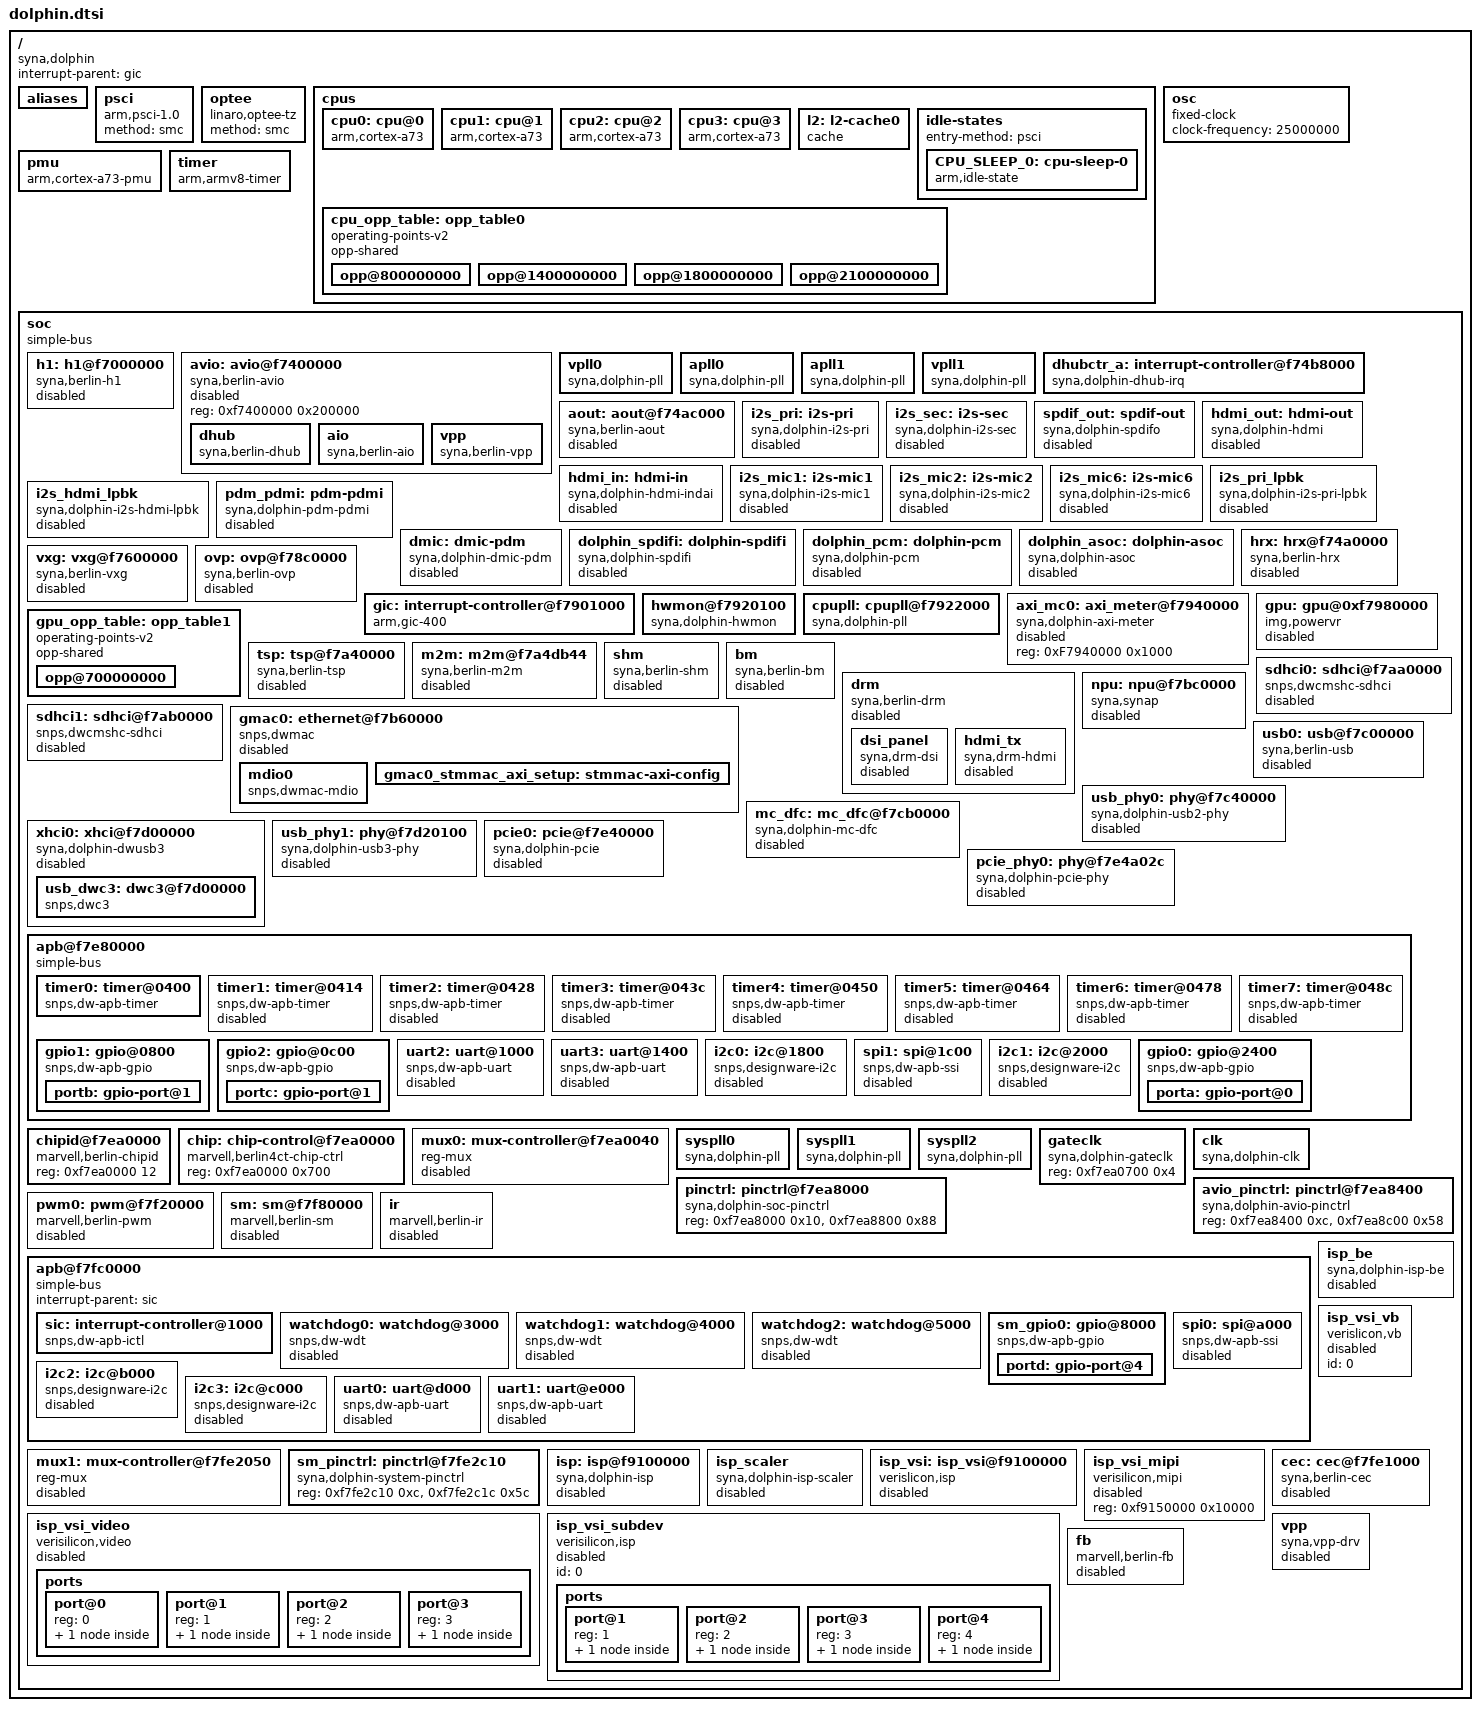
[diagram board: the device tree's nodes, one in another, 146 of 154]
/* SPDX-License-Identifier: GPL-2.0+ */
/*
* Copyright (C) 2016~2023 Synaptics Incorporated. All rights reserved.
*
* This program is free software; you can redistribute it and/or modify
* it under the terms of the GNU General Public License version 2 or
* later as published by the Free Software Foundation.
*
* INFORMATION CONTAINED IN THIS DOCUMENT IS PROVIDED "AS-IS," AND
* SYNAPTICS EXPRESSLY DISCLAIMS ALL EXPRESS AND IMPLIED WARRANTIES,
* INCLUDING ANY IMPLIED WARRANTIES OF MERCHANTABILITY AND FITNESS FOR
* A PARTICULAR PURPOSE, AND ANY WARRANTIES OF NON-INFRINGEMENT OF ANY
* INTELLECTUAL PROPERTY RIGHTS. IN NO EVENT SHALL SYNAPTICS BE LIABLE
* FOR ANY DIRECT, INDIRECT, INCIDENTAL, SPECIAL, PUNITIVE, OR
* CONSEQUENTIAL DAMAGES ARISING OUT OF OR IN CONNECTION WITH THE USE
* OF THE INFORMATION CONTAINED IN THIS DOCUMENT, HOWEVER CAUSED AND
* BASED ON ANY THEORY OF LIABILITY, WHETHER IN AN ACTION OF CONTRACT,
* NEGLIGENCE OR OTHER TORTIOUS ACTION, AND EVEN IF SYNAPTICS WAS
* ADVISED OF THE POSSIBILITY OF SUCH DAMAGE. IF A TRIBUNAL OF
* COMPETENT JURISDICTION DOES NOT PERMIT THE DISCLAIMER OF DIRECT
* DAMAGES OR ANY OTHER DAMAGES, SYNAPTICS' TOTAL CUMULATIVE LIABILITY
* TO ANY PARTY SHALL NOT EXCEED ONE HUNDRED U.S. DOLLARS.
*/

#include <dt-bindings/clock/dolphin.h>
#include <dt-bindings/interrupt-controller/arm-gic.h>

/ {
	compatible = "syna,dolphin";
	interrupt-parent = <&gic>;
	#address-cells = <2>;
	#size-cells = <2>;

	aliases {
		serial0 = &uart0;
		serial1 = &uart1;
		serial2 = &uart2;
		serial3 = &uart3;
		i2c0 = &i2c0;
		i2c1 = &i2c1;
		i2c2 = &i2c2;
		i2c3 = &i2c3;
		mmc0 = &sdhci0;
		mmc1 = &sdhci1;
	};

	psci {
		compatible = "arm,psci-1.0";
		method = "smc";
	};

	optee {
		compatible = "linaro,optee-tz";
		method = "smc";
	};

	cpus {
		#address-cells = <1>;
		#size-cells = <0>;

		cpu0: cpu@0 {
			compatible = "arm,cortex-a73";
			device_type = "cpu";
			reg = <0x0>;
			enable-method = "psci";
			next-level-cache = <&l2>;
			cpu-idle-states = <&CPU_SLEEP_0>;
			operating-points-v2 = <&cpu_opp_table>;
			clocks = <&cpupll 0>;
		};

		cpu1: cpu@1 {
			compatible = "arm,cortex-a73";
			device_type = "cpu";
			reg = <0x1>;
			enable-method = "psci";
			next-level-cache = <&l2>;
			cpu-idle-states = <&CPU_SLEEP_0>;
			operating-points-v2 = <&cpu_opp_table>;
			clocks = <&cpupll 0>;
		};

		cpu2: cpu@2 {
			compatible = "arm,cortex-a73";
			device_type = "cpu";
			reg = <0x2>;
			enable-method = "psci";
			next-level-cache = <&l2>;
			cpu-idle-states = <&CPU_SLEEP_0>;
			operating-points-v2 = <&cpu_opp_table>;
			clocks = <&cpupll 0>;
		};

		cpu3: cpu@3 {
			compatible = "arm,cortex-a73";
			device_type = "cpu";
			reg = <0x3>;
			enable-method = "psci";
			next-level-cache = <&l2>;
			cpu-idle-states = <&CPU_SLEEP_0>;
			operating-points-v2 = <&cpu_opp_table>;
			clocks = <&cpupll 0>;
		};

		l2: l2-cache0 {
			compatible = "cache";
		};

		idle-states {
			entry-method = "psci";
			CPU_SLEEP_0: cpu-sleep-0 {
				compatible = "arm,idle-state";
				local-timer-stop;
				arm,psci-suspend-param = <0x0010000>;
				entry-latency-us = <75>;
				exit-latency-us = <155>;
				min-residency-us = <50000>;
			};
		};

		cpu_opp_table: opp_table0 {
			compatible = "operating-points-v2";
			opp-shared;

			opp@800000000 {
				opp-hz = /bits/ 64 <800000000>;
				opp-microvolt = <800000 800000 900000>;
				clock-latency-ns = <12600000>;
			};

			opp@1400000000 {
				opp-hz = /bits/ 64 <1400000000>;
				opp-microvolt = <800000 800000 900000>;
				clock-latency-ns = <12600000>;
			};

			opp@1800000000 {
				opp-hz = /bits/ 64 <1800000000>;
				opp-microvolt = <800000 800000 900000>;
				clock-latency-ns = <12600000>;
				opp-suspend;
			};

			opp@2100000000 {
				opp-hz = /bits/ 64 <2100000000>;
				opp-microvolt = <900000 900000 900000>;
				clock-latency-ns = <12600000>;
			};
		};
	};

	osc: osc {
		compatible = "fixed-clock";
		#clock-cells = <0>;
		clock-frequency = <25000000>;
	};

	pmu {
		compatible = "arm,cortex-a73-pmu";
		interrupts = <GIC_SPI 23 IRQ_TYPE_LEVEL_HIGH>,
			     <GIC_SPI 24 IRQ_TYPE_LEVEL_HIGH>,
			     <GIC_SPI 25 IRQ_TYPE_LEVEL_HIGH>,
			     <GIC_SPI 26 IRQ_TYPE_LEVEL_HIGH>;
		interrupt-affinity = <&cpu0>,
				     <&cpu1>,
				     <&cpu2>,
				     <&cpu3>;
	};

	timer {
		compatible = "arm,armv8-timer";
		interrupts = <GIC_PPI 13 (GIC_CPU_MASK_SIMPLE(4) | IRQ_TYPE_LEVEL_LOW)>,
			     <GIC_PPI 14 (GIC_CPU_MASK_SIMPLE(4) | IRQ_TYPE_LEVEL_LOW)>,
			     <GIC_PPI 11 (GIC_CPU_MASK_SIMPLE(4) | IRQ_TYPE_LEVEL_LOW)>,
			     <GIC_PPI 10 (GIC_CPU_MASK_SIMPLE(4) | IRQ_TYPE_LEVEL_LOW)>;
	};

	soc {
		compatible = "simple-bus";
		#address-cells = <1>;
		#size-cells = <1>;
		ranges = <0 0 0 0xffffffff>;

		h1: h1@f7000000 {
			compatible = "syna,berlin-h1";
			reg = <0xf7000000 0x400000>;
			interrupts = <GIC_SPI 29 IRQ_TYPE_EDGE_RISING>;
			clocks = <&clk CLK_ENCODER>;
			status = "disabled";
		};

		avio: avio@f7400000 {
			#address-cells = <1>;
			#size-cells = <1>;
			compatible = "syna,berlin-avio";
			reg = <0xf7400000 0x200000>;
			ranges = <0 0xf7400000 0x200000>;
			status = "disabled";

			dhub {
				compatible = "syna,berlin-dhub";
				frame-rate = <60>;
				interrupts = <GIC_SPI 33 IRQ_TYPE_LEVEL_HIGH>;
				interrupt-names = "vpp_dhub";
			};

			aio {
				compatible = "syna,berlin-aio";
				reg = <0xAC000 0x400>, <0x98000 0x8000>;
				reg-names = "aio_base", "gbl_base";
				clocks = <&clk CLK_AIOSYS>, <&apll0 0>, <&apll1 0>;
				clock-names = "aio_sysclk", "audio0_clk", "audio1_clk";
			};

			vpp {
				compatible = "syna,berlin-vpp";
				clocks = <&vpll0 0>, <&vpll1 0>,
					<&clk CLK_AIOSYS>, <&clk CLK_TXESC>;
				clock-names = "avio_vclk0", "avio_dpiclk",
					"aio_sysclk", "avio_txescclk";
			};
		};

		vpll0: vpll0 {
			compatible = "syna,dolphin-pll";
			reg = <0xf749c004 0x20>, <0xf749c138 0x4>;
			#clock-cells = <1>;
			clocks = <&osc>;
			bypass-shift = /bits/ 8 <0>;
			pd-bypass;
		};

		apll0: apll0 {
			compatible = "syna,dolphin-pll";
			reg = <0xf749c028 0x20>, <0xf749c138 0x4>;
			#clock-cells = <1>;
			clocks = <&osc>;
			bypass-shift = /bits/ 8 <2>;
			pd-bypass;
		};

		apll1: apll1 {
			compatible = "syna,dolphin-pll";
			reg = <0xf749c04c 0x20>, <0xf749c138 0x4>;
			#clock-cells = <1>;
			clocks = <&osc>;
			bypass-shift = /bits/ 8 <3>;
			pd-bypass;
		};

		vpll1: vpll1 {
			compatible = "syna,dolphin-pll";
			reg = <0xf749c070 0x20>, <0xf749c138 0x4>;
			#clock-cells = <1>;
			clocks = <&osc>;
			bypass-shift = /bits/ 8 <1>;
			pd-bypass;
		};

		dhubctr_a: interrupt-controller@f74b8000 {
			compatible = "syna,dolphin-dhub-irq";
			interrupts = <GIC_SPI 34 IRQ_TYPE_LEVEL_HIGH>;
			reg = <0xf74b8000 0x418>;
			interrupt-controller;
			#interrupt-cells = <1>;
			#address-cells = <0>;
		};

		aout: aout@f74ac000 {
			compatible = "syna,berlin-aout";
			interrupt-parent = <&dhubctr_a>;
			interrupts = <0>, <2>, <7>, <14>;
			interrupt-names = "ma0", "loro", "hdmi", "spdif";
			status = "disabled";
		};

		i2s_pri: i2s-pri {
			compatible = "syna,dolphin-i2s-pri";
			status = "disabled";
			interrupt-parent = <&dhubctr_a>;
			interrupts = <0>;
			interrupt-names = "pri";
		};

		i2s_sec: i2s-sec {
			compatible = "syna,dolphin-i2s-sec";
			status = "disabled";
			interrupt-parent = <&dhubctr_a>;
			interrupts = <2>;
		};

		spdif_out: spdif-out {
			compatible = "syna,dolphin-spdifo";
			status = "disabled";
			interrupt-parent = <&dhubctr_a>;
			interrupts = <14>;
			interrupt-names = "spdifo";
		};

		hdmi_out: hdmi-out {
			compatible = "syna,dolphin-hdmi";
			status = "disabled";
			interrupt-parent = <&dhubctr_a>;
			interrupts = <7>;
			interrupt-names = "hdmi";
		};

		hdmi_in: hdmi-in {
			 compatible = "syna,dolphin-hdmi-indai";
			 status = "disabled";
		};

		i2s_mic1: i2s-mic1 {
			compatible = "syna,dolphin-i2s-mic1";
			status = "disabled";
			interrupt-parent = <&dhubctr_a>;
			interrupts = <5>;
		};

		i2s_mic2: i2s-mic2 {
			compatible = "syna,dolphin-i2s-mic2";
			status = "disabled";
			interrupt-parent = <&dhubctr_a>;
			interrupts = <6>;
		};

		i2s_mic6: i2s-mic6 {
			compatible = "syna,dolphin-i2s-mic6";
			status = "disabled";
			interrupt-parent = <&dhubctr_a>;
			interrupts = <15>;
		};

		i2s_pri_lpbk: i2s_pri_lpbk {
			compatible = "syna,dolphin-i2s-pri-lpbk";
			status = "disabled";
			interrupt-parent = <&dhubctr_a>;
			interrupts = <10>;
		};

		i2s_hdmi_lpbk: i2s_hdmi_lpbk {
			compatible = "syna,dolphin-i2s-hdmi-lpbk";
			status = "disabled";
			interrupt-parent = <&dhubctr_a>;
			interrupts = <11>;
		};

		pdm_pdmi: pdm-pdmi {
			compatible = "syna,dolphin-pdm-pdmi";
			status = "disabled";
			interrupt-parent = <&dhubctr_a>;
			interrupts = <4>;
		};

		dmic: dmic-pdm {
			compatible = "syna,dolphin-dmic-pdm";
			status = "disabled";
			interrupt-parent = <&dhubctr_a>;
			interrupts = <4>;
			interleaved-mode;
			interleaved-dummy-data;
		};

		dolphin_spdifi: dolphin-spdifi {
			compatible = "syna,dolphin-spdifi";
			status = "disabled";
			interrupt-parent = <&dhubctr_a>;
			/*Set spdif input margin value
			 *for different sample rate.
			 */
			sample-rate-32000-margin = <0x1F171717>;
			sample-rate-44100-margin = <0x1F171717>;
			sample-rate-48000-margin = <0x1F171717>;
			sample-rate-88000-margin = <0x1A101010>;
			sample-rate-96000-margin = <0x1A101010>;
			sample-rate-17600-margin = <0x0F080808>;
			sample-rate-192000-margin = <0x0F070707>;
			interrupts = <15>;
		};

		dolphin_pcm: dolphin-pcm {
			compatible = "syna,dolphin-pcm";
			status = "disabled";
		};

		dolphin_asoc: dolphin-asoc {
			compatible = "syna,dolphin-asoc";
			status = "disabled";
		};

		hrx: hrx@f74a0000 {
			compatible = "syna,berlin-hrx";
			interrupt-parent = <&dhubctr_a>;
			interrupts = <9>, <23>, <24>, <25>, <26>, <27>;
			interrupt-names = "mic3", "otg", "hdmirx", "ytg", "uvtg", "itg";
			reg = <0xf74a0000 0x8000>, <0xf7fe2400 0x404>, <0xf74ac400 0x03f0>;
			reg-names = "hrx_base", "edid_base", "vip_base";
			status = "disabled";

			/* EDID with 4K@60Hz support */
			edid = [
				00 FF FF FF FF FF FF 00 4F 2E 30 00 01 00 00 00
				0B 1F 01 03 80 73 41 78 0A CF 74 A3 57 4C B0 23
				09 48 4C 21 08 00 81 C0 81 40 81 80 01 01 01 01
				01 01 01 01 01 01 02 3A 80 18 71 38 2D 40 58 2C
				45 00 80 88 42 00 00 1A 02 3A 80 D0 72 38 2D 40
				10 2C 45 80 20 C2 31 00 00 1E 00 00 00 FC 00 48
				44 4D 49 0A 20 20 20 20 20 20 20 20 00 00 00 FD
				00 32 4B 0F 45 3C 00 0A 20 20 20 20 20 20 01 5C
				02 03 38 71 52 61 60 5F 5D 5E 10 1F 22 21 20 05
				14 04 13 12 11 02 01 23 0F 07 07 83 01 00 00 6D
				03 0C 00 10 00 38 3C 20 00 60 01 02 03 67 D8 5D
				C4 01 78 80 00 E2 00 CB 01 1D 00 72 51 D0 1A 20
				6E 28 55 00 C4 8E 21 00 00 18 00 00 00 00 00 00
				00 00 00 00 00 00 00 00 00 00 00 00 00 00 00 00
				00 00 00 00 00 00 00 00 00 00 00 00 00 00 00 00
				00 00 00 00 00 00 00 00 00 00 00 00 00 00 00 8C
			];
		};

		vxg: vxg@f7600000 {
			compatible = "syna,berlin-vxg";
			reg = <0xf7600000 0x200000>;
			interrupts = <GIC_SPI 1 IRQ_TYPE_EDGE_RISING>;
			clocks = <&clk CLK_DECODER>;
			status = "disabled";
		};

		ovp: ovp@f78c0000 {
			compatible = "syna,berlin-ovp";
			reg = <0xf78c0000 0x10000>;
			clocks = <&clk CLK_OVPCORE>;
			clock-names = "ovp_coreclk";
			interrupts = <GIC_SPI 57 IRQ_TYPE_LEVEL_HIGH>;
			interrupt-names = "ovp_intr";
			status = "disabled";
		};

		gic: interrupt-controller@f7901000 {
			compatible = "arm,gic-400";
			#interrupt-cells = <3>;
			#address-cells = <0>;
			interrupt-controller;
			reg = <0xf7901000 0x1000>,
			      <0xf7902000 0x2000>,
			      <0xf7904000 0x2000>,
			      <0xf7906000 0x2000>;
			interrupts = <GIC_PPI 9 (GIC_CPU_MASK_SIMPLE(4) | IRQ_TYPE_LEVEL_HIGH)>;
		};

		hwmon@f7920100 {
			compatible = "syna,dolphin-hwmon";
			reg = <0xf7920100 0x14>;
			interrupts = <GIC_SPI 72 IRQ_TYPE_LEVEL_HIGH>;
		};

		cpupll: cpupll@f7922000 {
			compatible = "syna,dolphin-pll";
			reg = <0xf7922000 0x20>, <0xf7ea0710 0x4>;
			#clock-cells = <1>;
			clocks = <&osc>, <&clk CLK_CPUFASTREF>;
			bypass-shift = /bits/ 8 <4>;
			suspend-resume;
		};

		axi_mc0: axi_meter@f7940000 {
			compatible = "syna,dolphin-axi-meter";
			reg = <0xF7940000 0x1000>;
			status = "disabled";
		};

		gpu: gpu@0xf7980000 {
			compatible = "img,powervr";
			reg = <0xf7980000 0x80000>;
			clocks = <&clk CLK_GFX3DCORE>, <&clk CLK_GFX3DSYS>;
			clock-names = "gfx3dcore", "gfx3dsys";
			interrupts = <GIC_SPI 20 IRQ_TYPE_LEVEL_HIGH>;
			operating-points-v2 = <&gpu_opp_table>;
			status = "disabled";
		};

		gpu_opp_table: opp_table1 {
			compatible = "operating-points-v2";
			opp-shared;

			opp@700000000 {
				opp-hz = /bits/ 64 <700000000>;
				clock-latency-ns = <500000>;
			};
		};

		tsp: tsp@f7a40000 {
			compatible = "syna,berlin-tsp";
			clocks = <&clk CLK_TSP>, <&clk CLK_TSPREF>;
			clock-names = "core", "ref";
			interrupts = <GIC_SPI 2 IRQ_TYPE_LEVEL_HIGH>;
			reg = <0xf7a40000 0x40000>;
			status = "disabled";
		};

		m2m: m2m@f7a4db44 {
			compatible = "syna,berlin-m2m";
			clocks = <&clk CLK_TSP>, <&clk CLK_TSPREF>;
			clock-names = "core", "ref";
			interrupts = <GIC_SPI 2 IRQ_TYPE_LEVEL_HIGH>;
			reg = <0xf7a4db44 0x40>;
			status = "disabled";
		};

		shm: shm {
			compatible = "syna,berlin-shm";
			status = "disabled";
		};

		bm: bm {
			compatible = "syna,berlin-bm";
			status = "disabled";
		};

		drm: drm {
			compatible = "syna,berlin-drm";
			status = "disabled";

			dsi_panel {
				compatible = "syna,drm-dsi";
				status = "disabled";
			};

			hdmi_tx {
				compatible = "syna,drm-hdmi";
				status= "disabled";
			};
		};

		sdhci0: sdhci@f7aa0000 {
			compatible = "snps,dwcmshc-sdhci";
			reg = <0xf7aa0000 0x1000>;
			interrupts = <GIC_SPI 13 IRQ_TYPE_LEVEL_HIGH>;
			clocks = <&clk CLK_EMMC>, <&gateclk CLK_EMMCSYS>;
			clock-names = "core", "bus";
			resets = <&chip 0x680 12 0 0>, <&chip 0x688 6 1 0>;
			reset-names = "host", "phy";
			phy-offset = <0x300>;
			bus-width = <8>;
			non-removable;
			no-sd;
			no-sdio;
			status = "disabled";
		};

		sdhci1: sdhci@f7ab0000 {
			compatible = "snps,dwcmshc-sdhci";
			reg = <0xf7ab0000 0x1000>;
			interrupts = <GIC_SPI 15 IRQ_TYPE_LEVEL_HIGH>;
			clocks = <&clk CLK_SD0>, <&gateclk CLK_SDIOSYS>;
			clock-names = "core", "bus";
			resets = <&chip 0x680 2 0 0 >, <&chip 0x688 5 1 0>;
			reset-names = "host", "phy";
			phy-offset = <0x300>;
			bus-width = <4>;
			status = "disabled";
		};

		gmac0: ethernet@f7b60000 {
			compatible = "snps,dwmac";
			reg = <0xf7b60000 0x2000>;
			interrupts = <GIC_SPI 43 IRQ_TYPE_LEVEL_HIGH>;
			interrupt-names = "macirq";
			clocks = <&clk CLK_GETHRGMII>, <&gateclk CLK_GETHRGMIISYS>;
			clock-names = "stmmaceth", "pclk";
			clk_csr = <1>;
			snps,multicast-filter-bins = <128>;
			snps,perfect-filter-entries = <16>;
			snps,pbl = <32>;
			rx-fifo-depth = <4096>;
			tx-fifo-depth = <4096>;
			snps,axi-config = <&gmac0_stmmac_axi_setup>;
			status = "disabled";

			mdio0: mdio0 {
				compatible = "snps,dwmac-mdio";
				#address-cells = <1>;
				#size-cells = <0>;
			};

			gmac0_stmmac_axi_setup: stmmac-axi-config {
				snps,wr_osr_lmt = <7>;
				snps,rd_osr_lmt = <7>;
			};
		};

		npu: npu@f7bc0000 {
			compatible = "syna,synap", "vivante,galcore";
			reg = <0xf7bc0000 0x40000>;
			resets = <&chip 0x668 0 1 0>;
			interrupts = <GIC_SPI 105 IRQ_TYPE_LEVEL_HIGH>;
			clocks = <&gateclk CLK_NPUAXI>, <&clk CLK_NPU>;
			clock-names = "sys", "core";
			status = "disabled";
		};

		usb0: usb@f7c00000 {
			compatible = "syna,berlin-usb";
			reg = <0xf7c00000 0x40000>;
			interrupts = <GIC_SPI 11 IRQ_TYPE_LEVEL_HIGH>;
			clocks = <&gateclk 0>;
			clock-names = "otg";
			phys = <&usb_phy0>;
			phy-names = "usb2-phy";
			resets = <&chip 0x688 3 1 0>, <&chip 0x688 4 1 0>, <&chip 0x680 9 0 0>;
			reset-names = "dwc2", "dwc2-ecc", "dwc2-sync";
			dr_mode = "otg";
			status = "disabled";
		};

		usb_phy0: phy@f7c40000 {
			compatible = "syna,dolphin-usb2-phy";
			reg = <0xf7c40000 0x100>;
			#phy-cells = <0>;
			resets = <&chip 0x688 2 1 0>;
			reset-names = "phy";
			status = "disabled";
		};

		mc_dfc: mc_dfc@f7cb0000 {
			compatible = "syna,dolphin-mc-dfc";
			reg = <0xf7cb0000 0x400>, <0xf7940000 0x400>;
			interrupts = <GIC_SPI 68 IRQ_TYPE_LEVEL_HIGH>;
			status = "disabled";
		};

		xhci0: xhci@f7d00000 {
			compatible = "syna,dolphin-dwusb3";
			clocks = <&clk CLK_USB3CORE>;
			clock-names = "core_clk";
			resets = <&chip 0x680 10 0 0>;
			reset-names = "rst-sync";
			phys = <&usb_phy1>;
			phy-names = "usb-phy";
			#address-cells = <1>;
			#size-cells = <1>;
			ranges;
			status = "disabled";
			usb_dwc3: dwc3@f7d00000 {
				compatible = "snps,dwc3";
				reg = <0xf7d00000 0x20000>;
				interrupts = <GIC_SPI 42 IRQ_TYPE_LEVEL_HIGH>;
				dr_mode = "host";
			};
		};

		usb_phy1: phy@f7d20100 {
			compatible = "syna,dolphin-usb3-phy";
			reg = <0xf7d20100 0x20>;
			#phy-cells = <0>;
			resets = <&chip 0x688 0 1 0>;
			reset-names = "phy";
			status = "disabled";
		};

		pcie0: pcie@f7e40000 {
			compatible = "syna,dolphin-pcie";
			reg = <0xf7e40000 0x8000>, <0xf7e4a000 0x28>, <0xe0000000 0x00800000>;
			reg-names = "dbi", "ctrl", "config";
			interrupts = <GIC_SPI 63 IRQ_TYPE_LEVEL_HIGH>, <GIC_SPI 50 IRQ_TYPE_LEVEL_HIGH>;
			clocks = <&gateclk CLK_PCIE0SYS>;
			resets = <&chip 0x688 1 1 0>;
			#address-cells = <3>;
			#size-cells = <2>;
			#interrupt-cells = <1>;
			interrupt-map-mask = <0 0 0 0>;
			interrupt-map = <0 0 0 0 &gic GIC_SPI 63 IRQ_TYPE_LEVEL_HIGH>;
			num-lanes = <2>;
			num-viewport = <4>;
			device_type = "pci";
			ranges = <0x81000000 0 0          0xe0800000 0 0x00800000
				  0x82000000 0 0xe1000000 0xe1000000 0 0x07000000>;
			phys = <&pcie_phy0>;
			phy-names = "pcie-phy";
			status = "disabled";
		};

		pcie_phy0: phy@f7e4a02c {
			compatible = "syna,dolphin-pcie-phy";
			reg = <0xf7e4a02c 0x1c>;
			resets = <&chip 0x688 7 1 0>;
			#phy-cells = <0>;
			status = "disabled";
		};

		apb@f7e80000 {
			compatible = "simple-bus";
			#address-cells = <1>;
			#size-cells = <1>;
			ranges = <0 0xf7e80000 0x10000>;

			timer0: timer@0400 {
				compatible = "snps,dw-apb-timer";
				reg = <0x0400 0x14>;
				clocks = <&clk CLK_APBCORE>;
				clock-names = "timer";
				clock-freq = <200000000>;
				interrupts = <GIC_SPI 83 IRQ_TYPE_LEVEL_HIGH>;
			};

			timer1: timer@0414 {
				compatible = "snps,dw-apb-timer";
				reg = <0x0414 0x14>;
				clocks = <&clk CLK_APBCORE>;
				clock-names = "timer";
				clock-freq = <200000000>;
				status = "disabled";
			};

			timer2: timer@0428 {
				compatible = "snps,dw-apb-timer";
				reg = <0x0428 0x14>;
				clocks = <&clk CLK_APBCORE>;
				clock-names = "timer";
				clock-freq = <200000000>;
				status = "disabled";
			};

			timer3: timer@043c {
				compatible = "snps,dw-apb-timer";
				reg = <0x043c 0x14>;
				clocks = <&clk CLK_APBCORE>;
				clock-names = "timer";
				clock-freq = <200000000>;
				status = "disabled";
			};

			timer4: timer@0450 {
				compatible = "snps,dw-apb-timer";
				reg = <0x0450 0x14>;
				clocks = <&clk CLK_APBCORE>;
				clock-names = "timer";
				clock-freq = <200000000>;
				status = "disabled";
			};

			timer5: timer@0464 {
				compatible = "snps,dw-apb-timer";
				reg = <0x0464 0x14>;
				clocks = <&clk CLK_APBCORE>;
				clock-names = "timer";
				clock-freq = <200000000>;
				status = "disabled";
			};

			timer6: timer@0478 {
				compatible = "snps,dw-apb-timer";
				reg = <0x0478 0x14>;
				clocks = <&clk CLK_APBCORE>;
				clock-names = "timer";
				clock-freq = <200000000>;
				status = "disabled";
			};

			timer7: timer@048c {
				compatible = "snps,dw-apb-timer";
				reg = <0x048c 0x14>;
				clocks = <&clk CLK_APBCORE>;
				clock-names = "timer";
				clock-freq = <200000000>;
				status = "disabled";
			};

			gpio1: gpio@0800 {
				compatible = "snps,dw-apb-gpio";
				dev_name = "gpio_soc_1";
				reg = <0x0800 0x400>;
				#address-cells = <1>;
				#size-cells = <0>;

				portb: gpio-port@1 {
					gpio-controller;
					#gpio-cells = <2>;
					ngpios = <32>;
					reg = <0>;
					interrupt-controller;
					#interrupt-cells = <2>;
					#address-cells = <0>;
					interrupts = <GIC_SPI 78 IRQ_TYPE_LEVEL_HIGH>;
				};
			};

			gpio2: gpio@0c00 {
				compatible = "snps,dw-apb-gpio";
				dev_name = "gpio_soc_2";
				reg = <0x0c00 0x400>;
				#address-cells = <1>;
				#size-cells = <0>;

				portc: gpio-port@1 {
					gpio-controller;
					#gpio-cells = <2>;
					ngpios = <32>;
					reg = <0>;
					interrupt-controller;
					#interrupt-cells = <2>;
					#address-cells = <0>;
					interrupts = <GIC_SPI 79 IRQ_TYPE_LEVEL_HIGH>;
				};
			};

			uart2: uart@1000 {
				compatible = "snps,dw-apb-uart";
				reg = <0x1000 0x100>;
				interrupts = <GIC_SPI 95 IRQ_TYPE_LEVEL_HIGH>;
				clocks = <&clk CLK_APBCORE>;
				reg-shift = <2>;
				status = "disabled";
			};

			uart3: uart@1400 {
				compatible = "snps,dw-apb-uart";
				reg = <0x1400 0x100>;
				interrupts = <GIC_SPI 96 IRQ_TYPE_LEVEL_HIGH>;
				clocks = <&clk CLK_APBCORE>;
				reg-shift = <2>;
				status = "disabled";
			};

			i2c0: i2c@1800 {
				compatible = "snps,designware-i2c";
				#address-cells = <1>;
				#size-cells = <0>;
				reg = <0x1800 0x100>;
				clocks = <&clk CLK_APBCORE>;
				i2c-sda-hold-time-ns = <449>;
				i2c-sda-falling-time-ns = <425>;
				i2c-scl-falling-time-ns = <205>;
				interrupts = <GIC_SPI 80 IRQ_TYPE_LEVEL_HIGH>;
				status = "disabled";
			};

			spi1: spi@1c00 {
				compatible = "snps,dw-apb-ssi";
				reg = <0x1c00 0x100>;
				#address-cells = <1>;
				#size-cells = <0>;
				num-cs = <4>;
				clocks = <&clk CLK_APBCORE>;
				interrupts = <GIC_SPI 82 IRQ_TYPE_LEVEL_HIGH>;
				status = "disabled";
			};

			i2c1: i2c@2000 {
				compatible = "snps,designware-i2c";
				#address-cells = <1>;
				#size-cells = <0>;
				reg = <0x2000 0x100>;
				clocks = <&clk CLK_APBCORE>;
				i2c-sda-hold-time-ns = <449>;
				i2c-sda-falling-time-ns = <425>;
				i2c-scl-falling-time-ns = <205>;
				interrupts = <GIC_SPI 81 IRQ_TYPE_LEVEL_HIGH>;
				status = "disabled";
			};

			gpio0: gpio@2400 {
				compatible = "snps,dw-apb-gpio";
				dev_name = "gpio_soc_0";
				reg = <0x2400 0x400>;
				#address-cells = <1>;
				#size-cells = <0>;

				porta: gpio-port@0 {
					gpio-controller;
					#gpio-cells = <2>;
					ngpios = <32>;
					reg = <0>;
					interrupt-controller;
					#interrupt-cells = <2>;
					#address-cells = <0>;
					interrupts = <GIC_SPI 77 IRQ_TYPE_LEVEL_HIGH>;
				};
			};
		};

		chipid@f7ea0000 {
			compatible = "marvell,berlin-chipid";
			reg = <0xf7ea0000 12>;
		};

		chip: chip-control@f7ea0000 {
			compatible = "marvell,berlin4ct-chip-ctrl";
			reg = <0xf7ea0000 0x700>;
			#reset-cells = <4>;
		};

		mux0: mux-controller@f7ea0040 {
			compatible = "reg-mux";
			reg = <0xf7ea0040 0x4>;
		        #mux-control-cells = <1>;
		        mux-reg-masks = <0x0 0x20>;
			status = "disabled";
		};

		syspll0: syspll0 {
			compatible = "syna,dolphin-pll";
			reg = <0xf7ea0200 0x20>, <0xf7ea0710 0x4>;
			#clock-cells = <1>;
			clocks = <&osc>;
			bypass-shift = /bits/ 8 <0>;
		};

		syspll1: syspll1 {
			compatible = "syna,dolphin-pll";
			reg = <0xf7ea0220 0x20>, <0xf7ea0710 0x4>;
			#clock-cells = <1>;
			clocks = <&osc>;
			bypass-shift = /bits/ 8 <1>;
		};

		syspll2: syspll2 {
			compatible = "syna,dolphin-pll";
			reg = <0xf7ea0240 0x20>, <0xf7ea0710 0x4>;
			#clock-cells = <1>;
			clocks = <&osc>;
			bypass-shift = /bits/ 8 <2>;
		};

		gateclk: gateclk {
			compatible = "syna,dolphin-gateclk";
			reg = <0xf7ea0700 0x4>;
			#clock-cells = <1>;
		};

		clk: clk {
			compatible = "syna,dolphin-clk";
			reg = <0xf7ea0720 0xf8>;
			#clock-cells = <1>;
			clocks = <&syspll0 0>, <&syspll2 0>, <&syspll0 1>, <&syspll1 1>, <&syspll2 1>, <&syspll1 0>;
		};

		pinctrl: pinctrl@f7ea8000 {
			compatible = "syna,dolphin-soc-pinctrl";
			reg = <0xf7ea8000 0x10>, <0xf7ea8800 0x88>;
		};

		avio_pinctrl: pinctrl@f7ea8400 {
			compatible = "syna,dolphin-avio-pinctrl";
			reg = <0xf7ea8400 0xc>, <0xf7ea8c00 0x58>;
		};

		pwm0: pwm@f7f20000 {
			compatible = "marvell,berlin-pwm";
			reg = <0xf7f20000 0x40>;
			clocks = <&clk CLK_CFG>;
			#pwm-cells = <3>;
			status = "disabled";
		};

		sm: sm@f7f80000 {
			compatible = "marvell,berlin-sm";
			reg = <0xf7f80000 0x20000>, <0xf7fe2014 4>;
			interrupts = <GIC_SPI 19 IRQ_TYPE_LEVEL_HIGH>;
			mode-bootloader = <0x29012002>;
			mode-recovery = <0x11092017>;
			mode-fastboot = <0x12510399>;
			mode-recovery,quiescent = <0x06012021>;
			mode-quiescent = <0x01112021>;
			status = "disabled";
		};

		ir: ir {
			compatible = "marvell,berlin-ir";
			status = "disabled";
		};

		apb@f7fc0000 {
			compatible = "simple-bus";
			#address-cells = <1>;
			#size-cells = <1>;
			ranges = <0 0xf7fc0000 0x10000>;
			interrupt-parent = <&sic>;

			sic: interrupt-controller@1000 {
				compatible = "snps,dw-apb-ictl";
				reg = <0x1000 0x30>;
				interrupt-controller;
				#interrupt-cells = <1>;
				#address-cells = <0>;
				interrupt-parent = <&gic>;
				interrupts = <GIC_SPI 17 IRQ_TYPE_LEVEL_HIGH>;
			};

			watchdog0: watchdog@3000 {
				compatible = "snps,dw-wdt";
				reg = <0x3000 0x100>;
				clocks = <&osc>;
				status = "disabled";
			};

			watchdog1: watchdog@4000 {
				compatible = "snps,dw-wdt";
				reg = <0x4000 0x100>;
				clocks = <&osc>;
				status = "disabled";
			};

			watchdog2: watchdog@5000 {
				compatible = "snps,dw-wdt";
				reg = <0x5000 0x100>;
				clocks = <&osc>;
				status = "disabled";
			};

			sm_gpio0: gpio@8000 {
				compatible = "snps,dw-apb-gpio";
				dev_name = "gpio_sm_0";
				reg = <0x8000 0x400>;
				#address-cells = <1>;
				#size-cells = <0>;
				no-suspend-resume;

				portd: gpio-port@4 {
					gpio-controller;
					#gpio-cells = <2>;
					ngpios = <32>;
					reg = <0>;
				};
			};

			spi0: spi@a000 {
				compatible = "snps,dw-apb-ssi";
				#address-cells = <1>;
				#size-cells = <0>;
				reg = <0xa000 0x100>;
				num-cs = <4>;
				clocks = <&osc>;
				interrupts = <5>;
				status = "disabled";
			};

			i2c2: i2c@b000 {
				compatible = "snps,designware-i2c";
				#address-cells = <1>;
				#size-cells = <0>;
				reg = <0xb000 0x100>;
				clocks = <&osc>;
				i2c-sda-hold-time-ns = <420>;
				i2c-sda-falling-time-ns = <500>;
				i2c-scl-falling-time-ns = <220>;
				interrupts = <6>;
				status = "disabled";
			};

			i2c3: i2c@c000 {
				compatible = "snps,designware-i2c";
				#address-cells = <1>;
				#size-cells = <0>;
				reg = <0xc000 0x100>;
				clocks = <&osc>;
				i2c-sda-hold-time-ns = <420>;
				i2c-sda-falling-time-ns = <500>;
				i2c-scl-falling-time-ns = <220>;
				interrupts = <7>;
				status = "disabled";
			};

			uart0: uart@d000 {
				compatible = "snps,dw-apb-uart";
				reg = <0xd000 0x100>;
				interrupts = <8>;
				clocks = <&osc>;
				reg-shift = <2>;
				status = "disabled";
			};

			uart1: uart@e000 {
				compatible = "snps,dw-apb-uart";
				reg = <0xe000 0x100>;
				interrupts = <9>;
				clocks = <&osc>;
				reg-shift = <2>;
				status = "disabled";
			};
		};

		mux1: mux-controller@f7fe2050 {
			compatible = "reg-mux";
			reg = <0xf7fe2050 0x4>;
		        #mux-control-cells = <1>;
		        mux-reg-masks = <0x0 0x1>;
			status = "disabled";
		};

		sm_pinctrl: pinctrl@f7fe2c10 {
			compatible = "syna,dolphin-system-pinctrl";
			reg = <0xf7fe2c10 0xc>, <0xf7fe2c1c 0x5c>;
		};

		isp: isp@f9100000 {
			status = "disabled";
			compatible = "syna,dolphin-isp";
			reg = <0xf9100000 0x100000>;
			clocks = <&clk CLK_TXESC>, <&clk CLK_ISP>, <&clk CLK_ISSSYS>, <&clk CLK_ISPBE>,
				 <&clk CLK_ISPDSC>, <&clk CLK_ISPCSI0>, <&clk CLK_ISPCSI1>;
			clock-names = "txescclk", "ispclk", "isssysclk", "ispbeclk",
				      "ispdscclk", "ispcsi0clk", "ispcsi1clk";
			resets = <&chip 0x688 8 1 0>;
			reset-names = "isprst";
			interrupts = <GIC_SPI 112 IRQ_TYPE_LEVEL_HIGH>,
				     <GIC_SPI 116 IRQ_TYPE_LEVEL_HIGH>;
			interrupt-names = "isp_core",
					  "isp_tsb_dhub";
		};

		isp_scaler: isp_scaler {
			status = "disabled";
			compatible = "syna,dolphin-isp-scaler";
		};

		isp_be: isp_be {
			status = "disabled";
			compatible = "syna,dolphin-isp-be";
		};

		isp_vsi: isp_vsi@f9100000{
			id = <0>;
			status = "disabled";
			compatible = "verislicon,isp";
			reg = <0xf9100000 0x100000>;
			interrupts = <GIC_SPI 112 IRQ_TYPE_LEVEL_HIGH>;
			interrupt-names = "isp_core";
		};

		isp_vsi_video: isp_vsi_video{
			status = "disabled";
			compatible = "verisilicon,video";

			ports {
				#address-cells = <1>;
				#size-cells = <0>;
				port@0 {
					reg = <0>;
					#address-cells = <1>;
					#size-cells = <0>;
					isp_vsi_video_ep0: endpoint@0 {
						reg = <0>;
						remote-endpoint = <&isp_vsi_subdev_ep0>;
					};
				};

				port@1 {
					reg = <1>;
					#address-cells = <1>;
					#size-cells = <0>;
					isp_vsi_video_ep1: endpoint@1 {
						reg = <1>;
						remote-endpoint = <&isp_vsi_subdev_ep1>;
					};
				};

				port@2 {
					reg = <2>;
					#address-cells = <1>;
					#size-cells = <0>;
					isp_vsi_video_ep2: endpoint@2 {
						reg = <2>;
						remote-endpoint = <&isp_vsi_subdev_ep2>;
					};
				};

				port@3 {
					reg = <3>;
					#address-cells = <1>;
					#size-cells = <0>;
					isp_vsi_video_ep3: endpoint@3 {
						reg = <3>;
						remote-endpoint = <&isp_vsi_subdev_ep3>;
					};
				};
			};
		};

		isp_vsi_vb: isp_vsi_vb{
			id = <0>;
			status = "disabled";
			compatible = "verislicon,vb";
		};

		isp_vsi_mipi: isp_vsi_mipi{
			status = "disabled";
			compatible = "verisilicon,mipi";
			reg = <0xf9150000 0x10000>;
		};

		isp_vsi_subdev: isp_vsi_subdev{
			id = <0>;
			status = "disabled";
			compatible = "verisilicon,isp";
			ports {
				#address-cells = <1>;
				#size-cells = <0>;
				port@1 {
					reg = <1>;
					#address-cells = <1>;
					#size-cells = <0>;
					isp_vsi_subdev_ep0: endpoint@1 {
						reg = <1>;
						remote-endpoint = <&isp_vsi_video_ep0>;
					};
				};

				port@2 {
					reg = <2>;
					#address-cells = <1>;
					#size-cells = <0>;
					isp_vsi_subdev_ep1: endpoint@2 {
						reg = <2>;
						remote-endpoint = <&isp_vsi_video_ep1>;
					};
				};

				port@3 {
					reg = <3>;
					#address-cells = <1>;
					#size-cells = <0>;
					isp_vsi_subdev_ep2: endpoint@3 {
						reg = <3>;
						remote-endpoint = <&isp_vsi_video_ep2>;
					};
				};

				port@4 {
					reg = <4>;
					#address-cells = <1>;
					#size-cells = <0>;
					isp_vsi_subdev_ep3: endpoint@4 {
						reg = <4>;
						remote-endpoint = <&isp_vsi_video_ep3>;
					};
				};
			};
		};

		cec: cec@f7fe1000 {
			compatible = "syna,berlin-cec";
			interrupt-parent = <&sic>;
			interrupts = <16>;
			reg = <0xf7fe1000 0x1000>;
			status = "disabled";
		};

		vpp: vpp {
			status = "disabled";
			compatible = "syna,vpp-drv";
			clocks = <&vpll0 0>, <&vpll1 0>;
			clock-names = "avio_vclk0", "avio_dpiclk";
			enable_ampless_boot = <1>;
		};

		fb: fb {
			compatible = "marvell,berlin-fb";
			status = "disabled";
			frame-size-ndx = <1>;
			disp-mode = <0>;
			disp1-res-id = <24>;
			disp1-type = <0>;
		};
	};
};
